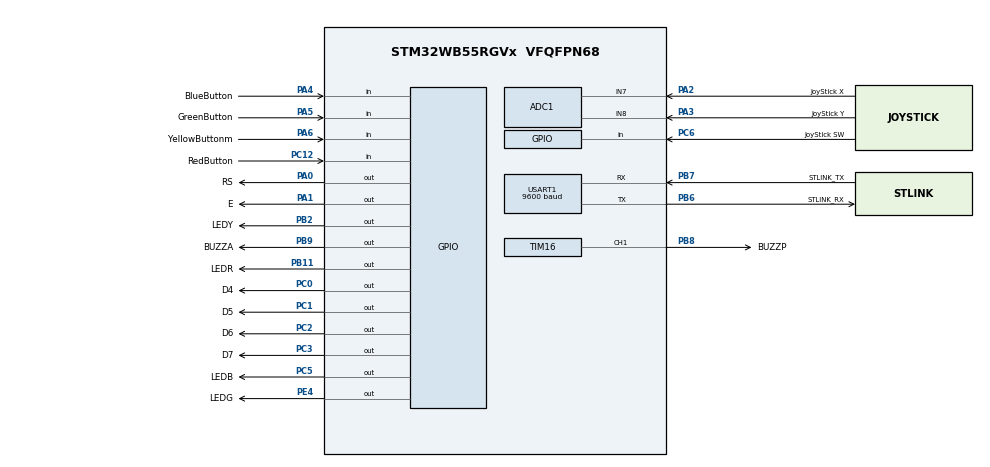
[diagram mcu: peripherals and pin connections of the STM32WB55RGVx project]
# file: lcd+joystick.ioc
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ADC1.Channel-0\#ChannelRegularConversion=ADC_CHANNEL_7
ADC1.NbrOfConversionFlag=1
ADC1.OffsetNumber-0\#ChannelRegularConversion=ADC_OFFSET_NONE
ADC1.Rank-0\#ChannelRegularConversion=1
ADC1.SamplingTime-0\#ChannelRegularConversion=ADC_SAMPLETIME_2CYCLES_5
ADC1.master=1
Mcu.Family=STM32WB
Mcu.Name=STM32WB55RGVx
Mcu.Package=VFQFPN68
NVIC.PriorityGroup=NVIC_PRIORITYGROUP_4
NVIC.TIM2_IRQn=true\:0\:0\:false\:false\:true\:true\:true\:true
OSC_IN.GPIO_Label=RCC_OSC_IN
OSC_IN.Signal=RCC_OSC_IN
OSC_OUT.GPIO_Label=RCC_OSC_OUT
OSC_OUT.Signal=RCC_OSC_OUT
PA0.GPIO_Label=RS
PA0.Signal=GPIO_Output
PA1.GPIO_Label=E
PA1.Signal=GPIO_Output
PA11.GPIO_Label=USB_DM
PA11.Signal=USB_DM
PA12.GPIO_Label=USB_DP
PA12.Signal=USB_DP
PA13.GPIO_Label=JTMS
PA13.Signal=SYS_JTMS-SWDIO
PA14.GPIO_Label=JTCK
PA14.Signal=SYS_JTCK-SWCLK
PA2.GPIO_Label=JoyStick X
PA2.Signal=ADCx_IN7
PA3.GPIO_Label=JoyStick Y
PA3.Signal=ADCx_IN8
PA4.GPIO_Label=BlueButton
PA4.GPIO_PuPd=GPIO_PULLUP
PA4.Signal=GPIO_Input
PA5.GPIO_Label=GreenButton
PA5.GPIO_PuPd=GPIO_PULLUP
PA5.Signal=GPIO_Input
PA6.GPIO_Label=YellowButtonm
PA6.GPIO_PuPd=GPIO_PULLUP
PA6.Signal=GPIO_Input
PB11.GPIO_Label=LEDR
PB11.Signal=GPIO_Output
PB2.GPIO_Label=LEDY
PB2.Signal=GPIO_Output
PB3.GPIO_Label=JTDO
PB3.Signal=SYS_JTDO-SWO
PB6.GPIO_Label=STLINK_RX
PB6.Mode=Asynchronous
PB6.Signal=USART1_TX
PB7.GPIO_Label=STLINK_TX
PB7.Mode=Asynchronous
PB7.Signal=USART1_RX
PB8.GPIO_Label=BUZZP
PB8.Signal=S_TIM16_CH1
PB9.GPIO_Label=BUZZA
PB9.Signal=GPIO_Output
PC0.GPIO_Label=D4
PC0.Signal=GPIO_Output
PC1.GPIO_Label=D5
PC1.Signal=GPIO_Output
PC12.GPIO_Label=RedButton
PC12.GPIO_PuPd=GPIO_PULLUP
PC12.Signal=GPIO_Input
PC13.GPIO_Label=SYS_WKUP2
PC13.Signal=SYS_WKUP2
PC14-OSC32_IN.GPIO_Label=RCC_OSC32_IN
PC14-OSC32_IN.Signal=RCC_OSC32_IN
PC15-OSC32_OUT.GPIO_Label=RCC_OSC32_OUT
PC15-OSC32_OUT.Signal=RCC_OSC32_OUT
PC2.GPIO_Label=D6
PC2.Signal=GPIO_Output
PC3.GPIO_Label=D7
PC3.Signal=GPIO_Output
PC5.GPIO_Label=LEDB
PC5.Signal=GPIO_Output
PC6.GPIO_Label=JoyStick SW
PC6.GPIO_PuPd=GPIO_PULLUP
PC6.Signal=GPIO_Input
PE4.GPIO_Label=LEDG
PE4.Signal=GPIO_Output
ProjectManager.HeapSize=0x200
ProjectManager.StackSize=0x400
ProjectManager.TargetToolchain=Makefile
RCC.ADCFreq_Value=48000000
RCC.AHB2CLKDivider=RCC_SYSCLK_DIV2
RCC.AHBFreq_Value=32000000
RCC.APB1Freq_Value=32000000
RCC.APB1TimFreq_Value=32000000
RCC.APB2Freq_Value=32000000
RCC.APB2TimFreq_Value=32000000
RCC.APB3Freq_Value=16000000
RCC.Cortex2_Div=SYSTICK_CLKSOURCE_HCLK_DIV8
RCC.CortexFreq_Value=32000000
RCC.HCLKFreq_Value=32000000
RCC.HSE_VALUE=32000000
RCC.HSI48_VALUE=48000000
RCC.HSI_VALUE=16000000
RCC.LSE_VALUE=32768
RCC.MSIClockRange=RCC_MSIRANGE_10
RCC.PLLM=RCC_PLLM_DIV2
RCC.PLLSAI1N=6
RCC.SMPSCLockSelection=RCC_SMPSCLKSOURCE_HSI
RCC.SMPSCLockSelectionVirtual=RCC_SMPSCLKSOURCE_HSI
RCC.SMPSCLockSelectionVirtualVirtual=RCC_SMPSCLKSOURCE_HSI
RCC.SMPSDivider=1
RCC.SYSCLKFreq_VALUE=32000000
RCC.USBFreq_Value=48000000
RCC.VCOOutputFreq_Value=128000000
SH.ADCx_IN7.0=ADC1_IN7,IN7-Single-Ended
SH.ADCx_IN8.0=ADC1_IN8,IN8-Single-Ended
SH.S_TIM16_CH1.0=TIM16_CH1,PWM Generation1 CH1
TIM16.Channel=TIM_CHANNEL_1
TIM16.Period=255
TIM16.Prescaler=189
TIM16.Pulse=127
TIM2.Period=100000
TIM2.Prescaler=31
USART1.BaudRate=9600
USART1.VirtualMode-Asynchronous=VM_ASYNC
VP_MEMORYMAP_VS_MEMORYMAP.Mode=CurAppReg
VP_TIM16_VS_ClockSourceINT.Mode=Enable_Timer
VP_TIM2_VS_ClockSourceINT.Mode=Internal
board=P-NUCLEO-WB55-NUCLEO

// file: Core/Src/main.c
/* USER CODE BEGIN Header */
/**
  ******************************************************************************
  * @file           : main.c
  * @brief          : Main program body
  ******************************************************************************
  * @attention
  *
  * Copyright (c) 2025 STMicroelectronics.
  * All rights reserved.
  *
  * This software is licensed under terms that can be found in the LICENSE file
  * in the root directory of this software component.
  * If no LICENSE file comes with this software, it is provided AS-IS.
  *
  ******************************************************************************
  */
/* USER CODE END Header */
#include "main.h"
#include "adc.h"
#include "tim.h"
#include "usart.h"
#include "gpio.h"

/* USER CODE BEGIN Includes */
#include "SimonGame.h"
#include "lcd1602.h"
#include <stdio.h>
#include <string.h>
/* USER CODE END Includes */

/* USER CODE BEGIN PV */
Joystick_HandleTypeDef joystick;
// static int redButtonPressed = 0;
// static int blueButtonPressed = 0;
// static int yellowButtonPressed = 0;
// static int greenButtonPressed = 0;
/* USER CODE END PV */

void SystemClock_Config(void);
void PeriphCommonClock_Config(void);

/* USER CODE BEGIN 0 */
// int debounce(GPIO_TypeDef *GPIO, uint16_t Pin)
// {
//   // if(HAL_GPIO_ReadPin(GPIO, Pin) == GPIO_PIN_RESET)
//   // {
//   //   HAL_Delay(20);
//     if(HAL_GPIO_ReadPin(GPIO, Pin) == GPIO_PIN_RESET)
//     { return 1; }
//   //}

//   return 0;
// }

// /**
//  * @brief  Timer period elapsed callback.
//  * @param  htim: Pointer to a TIM_HandleTypeDef structure that contains
//  *                the configuration information for TIM module.
//  */
// void HAL_TIM_PeriodElapsedCallback(TIM_HandleTypeDef *htim)
// {
//   static char msg[500];
//     if (htim->Instance == TIM2)
//     {
//       if(debounce(RedButton_GPIO_Port, RedButton_Pin) && !redButtonPressed)
//       {
//         redButtonPressed = 1;
//         snprintf(msg, sizeof(msg), "Red pressed\r\n");
//         HAL_UART_Transmit(&huart1, (uint8_t*)msg, strlen(msg), 1000);
//       }

//       if(debounce(BlueButton_GPIO_Port, BlueButton_Pin) && !blueButtonPressed)
//       {
//         blueButtonPressed = 1;
//         snprintf(msg, sizeof(msg), "Blue pressed\r\n");
//         HAL_UART_Transmit(&huart1, (uint8_t*)msg, strlen(msg), 1000);
//       }

//       if(debounce(YellowButtonm_GPIO_Port, YellowButtonm_Pin) && !yellowButtonPressed)
//       {
//         yellowButtonPressed = 1;
//         snprintf(msg, sizeof(msg), "Yellow pressed\r\n");
//         HAL_UART_Transmit(&huart1, (uint8_t*)msg, strlen(msg), 1000);
//       }

//       if(debounce(GreenButton_GPIO_Port, GreenButton_Pin) && !greenButtonPressed)
//       {
//         greenButtonPressed = 1;
//         snprintf(msg, sizeof(msg), "Green pressed\r\n");
//         HAL_UART_Transmit(&huart1, (uint8_t*)msg, strlen(msg), 1000);
//       }
//     }
// }
/* USER CODE END 0 */

int main(void)
{

  /* MCU Configuration--------------------------------------------------------*/

  /* Reset of all peripherals, Initializes the Flash interface and the Systick. */
  HAL_Init();

  /* Configure the system clock */
  SystemClock_Config();

  /* Configure the peripherals common clocks */
  PeriphCommonClock_Config();

  /* Initialize all configured peripherals */
  MX_GPIO_Init();
  MX_ADC1_Init();
  MX_USART1_UART_Init();
  MX_TIM2_Init();
  MX_TIM16_Init();
  /* USER CODE BEGIN 2 */
  HAL_TIM_Base_Start_IT(&htim2);
  /*** Initialize LCD ***/
  LCD_Init();
  LCD_Cls();
  /*** End of LCD Initialization ***/

  /*** Initialize Joystick ***/
  Joystick_Init(&joystick, &hadc1, ADC_CHANNEL_7, ADC_CHANNEL_8,
                 GPIOC, GPIO_PIN_6);
  Joystick_Calibrate(&joystick);
  /*** End of Joystick Initialization ***/

  /* Initialize Game */
  Game play;
  Game_Init(&play);
  /* USER CODE END 2 */

  /* Infinite loop */
  while (1)
  {

    /* USER CODE BEGIN 3 */
    Game_Run(&play, &joystick);
  }
  /* USER CODE END 3 */
}

void SystemClock_Config(void)
{
  RCC_OscInitTypeDef RCC_OscInitStruct = {0};
  RCC_ClkInitTypeDef RCC_ClkInitStruct = {0};

  /** Macro to configure the PLL multiplication factor
  */
  __HAL_RCC_PLL_PLLM_CONFIG(RCC_PLLM_DIV2);

  /** Macro to configure the PLL clock source
  */
  __HAL_RCC_PLL_PLLSOURCE_CONFIG(RCC_PLLSOURCE_MSI);

  /** Configure the main internal regulator output voltage
  */
  __HAL_PWR_VOLTAGESCALING_CONFIG(PWR_REGULATOR_VOLTAGE_SCALE1);

  /** Initializes the RCC Oscillators according to the specified parameters
  * in the RCC_OscInitTypeDef structure.
  */
  RCC_OscInitStruct.OscillatorType = RCC_OSCILLATORTYPE_HSI|RCC_OSCILLATORTYPE_MSI;
  RCC_OscInitStruct.HSIState = RCC_HSI_ON;
  RCC_OscInitStruct.MSIState = RCC_MSI_ON;
  RCC_OscInitStruct.HSICalibrationValue = RCC_HSICALIBRATION_DEFAULT;
  RCC_OscInitStruct.MSICalibrationValue = RCC_MSICALIBRATION_DEFAULT;
  RCC_OscInitStruct.MSIClockRange = RCC_MSIRANGE_10;
  RCC_OscInitStruct.PLL.PLLState = RCC_PLL_NONE;
  if (HAL_RCC_OscConfig(&RCC_OscInitStruct) != HAL_OK)
  {
    Error_Handler();
  }

  /** Configure the SYSCLKSource, HCLK, PCLK1 and PCLK2 clocks dividers
  */
  RCC_ClkInitStruct.ClockType = RCC_CLOCKTYPE_HCLK4|RCC_CLOCKTYPE_HCLK2
                              |RCC_CLOCKTYPE_HCLK|RCC_CLOCKTYPE_SYSCLK
                              |RCC_CLOCKTYPE_PCLK1|RCC_CLOCKTYPE_PCLK2;
  RCC_ClkInitStruct.SYSCLKSource = RCC_SYSCLKSOURCE_MSI;
  RCC_ClkInitStruct.AHBCLKDivider = RCC_SYSCLK_DIV1;
  RCC_ClkInitStruct.APB1CLKDivider = RCC_HCLK_DIV1;
  RCC_ClkInitStruct.APB2CLKDivider = RCC_HCLK_DIV1;
  RCC_ClkInitStruct.AHBCLK2Divider = RCC_SYSCLK_DIV2;
  RCC_ClkInitStruct.AHBCLK4Divider = RCC_SYSCLK_DIV1;

  if (HAL_RCC_ClockConfig(&RCC_ClkInitStruct, FLASH_LATENCY_1) != HAL_OK)
  {
    Error_Handler();
  }
}

void PeriphCommonClock_Config(void)
{
  RCC_PeriphCLKInitTypeDef PeriphClkInitStruct = {0};

  /** Initializes the peripherals clock
  */
  PeriphClkInitStruct.PeriphClockSelection = RCC_PERIPHCLK_SMPS;
  PeriphClkInitStruct.SmpsClockSelection = RCC_SMPSCLKSOURCE_HSI;
  PeriphClkInitStruct.SmpsDivSelection = RCC_SMPSCLKDIV_RANGE0;

  if (HAL_RCCEx_PeriphCLKConfig(&PeriphClkInitStruct) != HAL_OK)
  {
    Error_Handler();
  }
}

void Error_Handler(void)
{
  __disable_irq();
  while (1)
  {
  }
}
